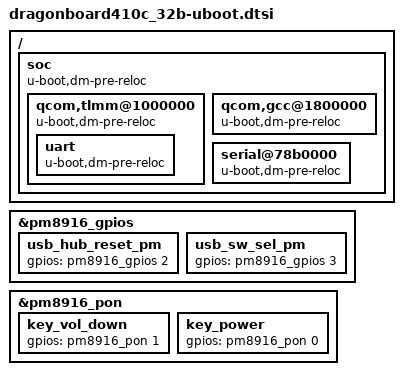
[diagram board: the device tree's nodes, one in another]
// SPDX-License-Identifier: GPL-2.0+
/*
 * U-Boot addition for Dragonboard 410c 32bit
 *
 * (C) Copyright 2018 Ramon Fried <ramon.fried@gmail.com>
 */

/ {
	soc {
		u-boot,dm-pre-reloc;

	qcom,tlmm@1000000 {
		u-boot,dm-pre-reloc;

		uart {
			u-boot,dm-pre-reloc;
		};
	};

	qcom,gcc@1800000 {
		u-boot,dm-pre-reloc;
	};

	serial@78b0000 {
		u-boot,dm-pre-reloc;
		};
	};
};

&pm8916_gpios {
	usb_hub_reset_pm {
		gpios = <&pm8916_gpios 2 0>;
	};

	usb_sw_sel_pm {
		gpios = <&pm8916_gpios 3 0>;
	};
};

&pm8916_pon {
	key_vol_down {
		gpios = <&pm8916_pon 1 0>;
	};

	key_power {
		gpios = <&pm8916_pon 0 0>;
	};
};
